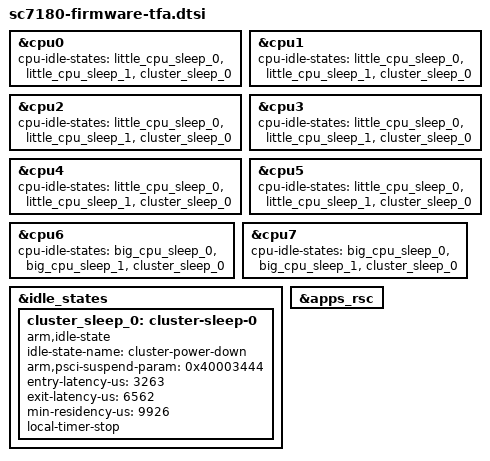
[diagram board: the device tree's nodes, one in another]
// SPDX-License-Identifier: BSD-3-Clause

/*
 * Devices that use SC7180 with TrustedFirmware-A
 * need PSCI PC mode instead of the OSI mode provided
 * by Qualcomm firmware.
 */

&cpu0 {
	/delete-property/ power-domains;
	/delete-property/ power-domain-names;

	cpu-idle-states = <&little_cpu_sleep_0
			   &little_cpu_sleep_1
			   &cluster_sleep_0>;
};

&cpu1 {
	/delete-property/ power-domains;
	/delete-property/ power-domain-names;

	cpu-idle-states = <&little_cpu_sleep_0
			   &little_cpu_sleep_1
			   &cluster_sleep_0>;
};

&cpu2 {
	/delete-property/ power-domains;
	/delete-property/ power-domain-names;

	cpu-idle-states = <&little_cpu_sleep_0
			   &little_cpu_sleep_1
			   &cluster_sleep_0>;
};

&cpu3 {
	/delete-property/ power-domains;
	/delete-property/ power-domain-names;

	cpu-idle-states = <&little_cpu_sleep_0
			   &little_cpu_sleep_1
			   &cluster_sleep_0>;
};

&cpu4 {
	/delete-property/ power-domains;
	/delete-property/ power-domain-names;

	cpu-idle-states = <&little_cpu_sleep_0
			   &little_cpu_sleep_1
			   &cluster_sleep_0>;
};

&cpu5 {
	/delete-property/ power-domains;
	/delete-property/ power-domain-names;

	cpu-idle-states = <&little_cpu_sleep_0
			   &little_cpu_sleep_1
			   &cluster_sleep_0>;
};

&cpu6 {
	/delete-property/ power-domains;
	/delete-property/ power-domain-names;

	cpu-idle-states = <&big_cpu_sleep_0
			   &big_cpu_sleep_1
			   &cluster_sleep_0>;
};

&cpu7 {
	/delete-property/ power-domains;
	/delete-property/ power-domain-names;

	cpu-idle-states = <&big_cpu_sleep_0
			   &big_cpu_sleep_1
			   &cluster_sleep_0>;
};

/delete-node/ &domain_idle_states;

&idle_states {
	cluster_sleep_0: cluster-sleep-0 {
		compatible = "arm,idle-state";
		idle-state-name = "cluster-power-down";
		arm,psci-suspend-param = <0x40003444>;
		entry-latency-us = <3263>;
		exit-latency-us = <6562>;
		min-residency-us = <9926>;
		local-timer-stop;
	};
};

/delete-node/ &cpu_pd0;
/delete-node/ &cpu_pd1;
/delete-node/ &cpu_pd2;
/delete-node/ &cpu_pd3;
/delete-node/ &cpu_pd4;
/delete-node/ &cpu_pd5;
/delete-node/ &cpu_pd6;
/delete-node/ &cpu_pd7;
/delete-node/ &cluster_pd;

&apps_rsc {
	/delete-property/ power-domains;
};
